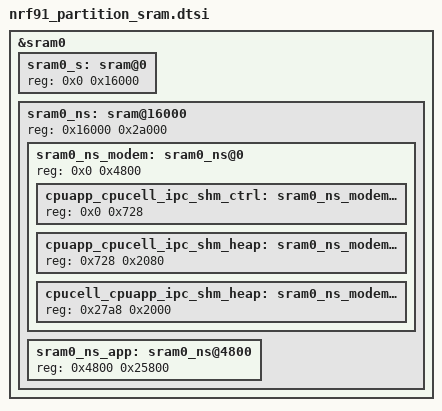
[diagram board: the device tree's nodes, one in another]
/*
 * Copyright (c) 2026 Nordic Semiconductor ASA
 *
 * SPDX-License-Identifier: LicenseRef-Nordic-5-Clause
 */

&sram0 {
	/*
	 * 0x2000_0000  Secure RAM                   (32 KB)
	 * 0x2000_8000  Non-secure RAM area          (224 KB)
	 *   0x2000_8000  Modem shared area            (18 KB)
	 *     0x2000_8000  control                      (1832 B)
	 *     0x2000_8728  app -> cell                  (8320 B)
	 *     0x2000_a7a8  cell -> app                  (8 KB)
	 *   0x2000_c800  Application RAM              (206 KB)
	 */

	sram0_s: sram@0 {
		/* Secure image memory — must match S_DATA_SIZE in region_defs.h */
		reg = <0x0 0x16000>;
	};

	sram0_ns: sram@16000 {
		/* Non-Secure image memory (168 KB) */
		reg = <0x16000 0x2a000>;
		#address-cells = <1>;
		#size-cells = <1>;
		ranges = <0x0 0x16000 0x2a000>;

		sram0_ns_modem: sram0_ns@0 {
			/* Modem (shared) memory */
			reg = <0x0 0x4800>;
			#address-cells = <1>;
			#size-cells = <1>;
			ranges = <0x0 0x0 0x4800>;

			cpuapp_cpucell_ipc_shm_ctrl: sram0_ns_modem@0 {
				/* Modem IPC control */
				reg = <0x0 0x728>;
			};

			cpuapp_cpucell_ipc_shm_heap: sram0_ns_modem@728 {
				/* Modem IPC transmit */
				reg = <0x728 0x2080>;
			};

			cpucell_cpuapp_ipc_shm_heap: sram0_ns_modem@27a8 {
				/* Modem IPC receive */
				reg = <0x27a8 0x2000>;
			};
		};

		sram0_ns_app: sram0_ns@4800 {
			/* Non-Secure application memory */
			reg = <0x4800 0x25800>;
		};
	};
};
